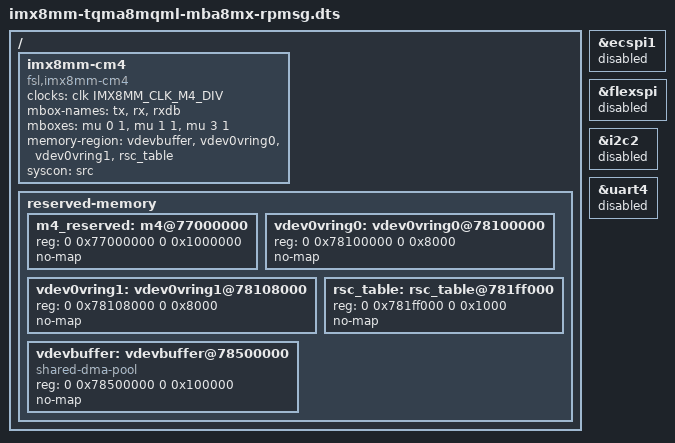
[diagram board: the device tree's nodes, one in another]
// SPDX-License-Identifier: (GPL-2.0-or-later OR MIT)
/*
 * Copyright 2021-2022 TQ-Systems GmbH
 * Author: Alexander Stein <linux@ew.tq-group.com>
 */

#include "imx8mm-tqma8mqml-mba8mx.dts"

/ {
	imx8mm-cm4 {
		compatible = "fsl,imx8mm-cm4";
		clocks = <&clk IMX8MM_CLK_M4_DIV>;
		mbox-names = "tx", "rx", "rxdb";
		mboxes = <&mu 0 1
			  &mu 1 1
			  &mu 3 1>;
		memory-region = <&vdevbuffer>, <&vdev0vring0>,
				<&vdev0vring1>, <&rsc_table>;
		syscon = <&src>;
	};

	reserved-memory {
		#address-cells = <2>;
		#size-cells = <2>;
		ranges;

		/*
		 * 0x7700_0000 ~ 0x77FF_FFFF is reserved for M4
		 * Must not be used from code running on Cortex-A cluster
		 * Must be in sync with linker settings for M4
		 */
		m4_reserved: m4@77000000 {
			reg = <0 0x77000000 0 0x1000000>;
			no-map;
		};

		vdev0vring0: vdev0vring0@78100000 {
			reg = <0 0x78100000 0 0x8000>;
			no-map;
		};

		vdev0vring1: vdev0vring1@78108000 {
			reg = <0 0x78108000 0 0x8000>;
			no-map;
		};

		/* Note: The underscore in node name is important! */
		rsc_table: rsc_table@781ff000 {
			reg = <0 0x781ff000 0 0x1000>;
			no-map;
		};

		vdevbuffer: vdevbuffer@78500000 {
			compatible = "shared-dma-pool";
			reg = <0 0x78500000 0 0x100000>;
			no-map;
		};
	};
};

/*
 * ATTENTION: M4 may use following IPs:
 * UART4, I2C2, ECSPI2, FLEXSPI
 * if access to more hardware is needed, keep in mind to disable it to prevent
 * system lockup and other things. Also resource partitioning using RDC
 * should beimplemented. See TF-A implementation.
 */

&ecspi1 {
	status = "disabled";
};

&flexspi {
	status = "disabled";
};

&i2c2 {
	status = "disabled";
};

&uart4 {
	status = "disabled";
};
